# hercules_dcan_spec_1.4.1 register map
Vendor: Texas Instruments
Peripheral module from a debugger description file (folder hercules).
Registers are 32-bit, read-only, reset 0x0 unless marked. A register's access mark holds for its fields unless they carry their own. Offsets are as the file gives them; lines under a group give offsets from that group; [hi:lo] are bit positions; {n}, {i} and the like mark numbered series; 'fields as' and 'values as' point back to an identical list; <NAME> marks a mode.

## Dcan
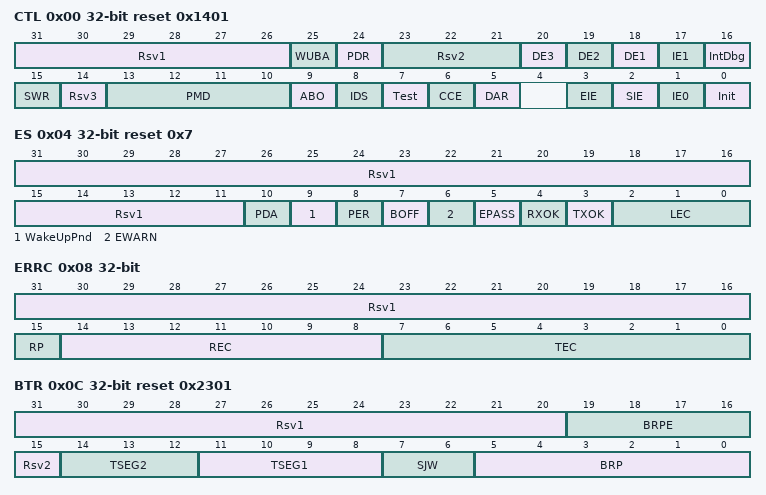
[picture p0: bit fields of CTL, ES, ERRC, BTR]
0x00 CTL access per field reset 0x1401 — CAN Control Register
  [31:26] Rsv1 ro — Reserved
  [25] WUBA rw — 1 = Enables Auto Wake Up on Bus Activity
  [24] PDR rw — 1 = Requests Local Low Power Down Mode
  [23:21] Rsv2 ro — Reserved
  [20] DE3 rw — 1 = Enable DMA Request for IF3
  [19] DE2 rw — 1 = Enable DMA Request for IF2
  [18] DE1 rw — 1 = Enable DMA Request for IF1
  [17] IE1 rw — 1 = Enables DCAN1INT
  [16] IntDbg ro — 1 = Debug Mode Requested and Entered
  [15] SWR rw — 1 = Software Reset Enable
  [14] Rsv3 ro — Reserved
  [13:10] PMD rw — 0xA=SECDED Disabled, Otherwise Enabled
  [9] ABO rw — 1 = Auto Bus On Enabled
  [8] IDS rw — 1 = Interrupt Transmission and Enter Debug Immediately
  [7] Test rw — 1 = Test Mode Enable
  [6] CCE rw — 1 = Configuration Change Enable (BTR Configuration)
  [5] DAR rw — 1 = Disable Automatic Retransmission
  [3] EIE rw — 1 = PER, BOFF, and EWARN Errors Enabled to generate DCAN0INT
  [2] SIE rw — 1 = WakeUpPnd, RxOk, and LEC Bits Generate DCAN0INT
  [1] IE0 rw — 1 = Interrupt Enable for DCAN0INT
  [0] Init rw — 1 = Initialization Mode Entered
0x04 ES access per field reset 0x7 — Error and Status register
  [31:11] Rsv1 ro — Reserved
  [10] PDA rw — 1 = DCAN Is Powered Down
  [9] WakeUpPnd rw — 1 = DCAN Initiated a WakeUp To System
  [8] PER rw — 1 = SECDED Detected Single/Double Bit Error
  [7] BOFF rw — 1 = BUS Off State
  [6] EWARN rw — 1 = Error Warning State, 1+ Error Counter >= 96
  [5] EPASS rw — 1 = Error Passive State
  [4] RXOK ro — 1 = Message Successfully Received
  [3] TXOK rw — 1 = Message Successfully Transmitted
  [2:0] LEC rw — 1 = Initialization Mode Entered
0x08 ERRC — Error Counter Register
  [31:16] Rsv1 — Reserved
  [15] RP — Receive Error Passive
  [14:8] REC — Receive Error Count
  [7:0] TEC — Transmit Error Count
0x0C BTR access per field reset 0x2301 — BIT Timing Register
  [31:20] Rsv1 ro — Reserved
  [19:16] BRPE rw — Baud Rate Prescaler Extension
  [15] Rsv2 ro — Reserved
  [14:12] TSEG2 rw — Time Segment After Sample Point
  [11:8] TSEG1 rw — Time Segment Before Sample Point
  [7:6] SJW rw — Sync Jump Width
  [5:0] BRP rw — Baud Rate Prescaler
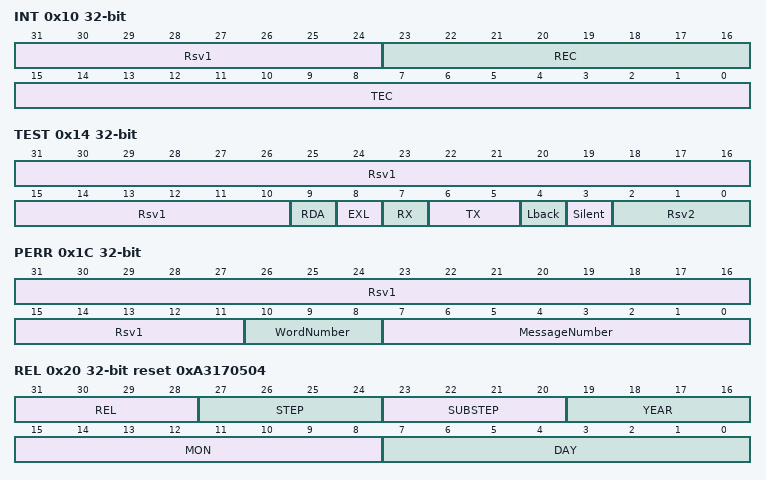
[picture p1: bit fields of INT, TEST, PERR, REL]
0x10 INT — Interrupt Register
  [31:24] Rsv1 — Reserved
  [23:16] REC — Int1ID 0x00 = No Int, 0x01-0x80 = Message Object #, Others Unused
  [15:0] TEC — Int0ID 0x00 = No Int, 0x01-0x80 = Message Object #, 0x8000 = Error Interrupt, Others Unused
0x14 TEST access per field
  [31:10] Rsv1 ro — Reserved
  [9] RDA rw — 1 = Enable Direct Access to RAM in Test Mode
  [8] EXL rw — 1 = Enable External Loopback
  [7] RX ro — 0 = CAN Bus is Dominant, 1=Recessive
  [6:5] TX rw — Control CANTX 0=Normal,1=Sample Pt. Monitor, 2= Drive Dom., 3=Drive Rec.
  [4] Lback rw — 1 = Enable Loopback
  [3] Silent rw — 1 = Silent Mode Enabled
  [2:0] Rsv2 ro — Reserved
0x1C PERR — Parity Error Code Register
  [31:11] Rsv1 — Reserved
  [10:8] WordNumber — Reserved - Always Reads 0
  [7:0] MessageNumber — 0x1-0x80 Message Number where Double Bit Error Detected
0x20 REL reset 0xA3170504 — Core Release Register
  [31:28] REL — Core Release
  [27:24] STEP — Step of Core Release
  [23:20] SUBSTEP — Substep of Core Release
  [19:16] YEAR
  [15:8] MON — Month
  [7:0] DAY
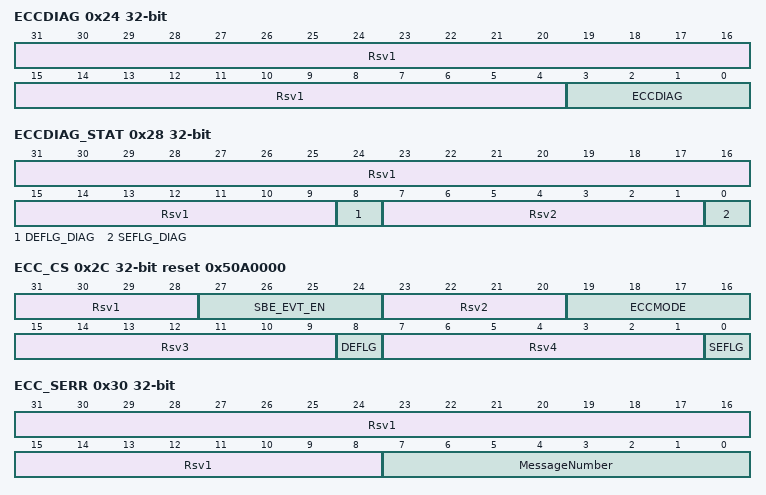
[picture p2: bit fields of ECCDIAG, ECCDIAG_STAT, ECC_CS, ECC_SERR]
0x24 ECCDIAG access per field — ECC Diagnostic Register
  [31:4] Rsv1 ro — Reserved
  [3:0] ECCDIAG rw — Diagnostic Mode 0x5=Enabled, 0xA=Disabled
0x28 ECCDIAG_STAT — ECC Diagnostic Status Register
  [31:9] Rsv1 — Reserved
  [8] DEFLG_DIAG — 1 = Double Bit Error Detected in Diagnostic Mode
  [7:1] Rsv2 — Reserved
  [0] SEFLG_DIAG — 1 = Single Bit Error Detected in Diagnostic Mode
0x2C ECC_CS access per field reset 0x50A0000 — ECC Control and Status Register
  [31:28] Rsv1 ro — Reserved
  [27:24] SBE_EVT_EN rw — 0x5 SECDED single bit error event disabled, Others Enabled
  [23:20] Rsv2 ro — Reserved
  [19:16] ECCMODE rw — 0x5 SECDED Disabled, Others SECDED Enabled
  [15:9] Rsv3 ro — Reserved
  [8] DEFLG rw — 1 = Double Bit Error Detected
  [7:1] Rsv4 ro — Reserved
  [0] SEFLG rw — 1 = Single Bit Error Detected
0x30 ECC_SERR — ECC Single Bit Error Code Register
  [31:8] Rsv1 — Reserved
  [7:0] MessageNumber — 0x1-0x80 Message Number where Double Bit Error Detected
0x80 ABOTR rw — Auto-Bus-On Time Register
  [31:0] ABO_TIME — Auto Bus On Time Counter
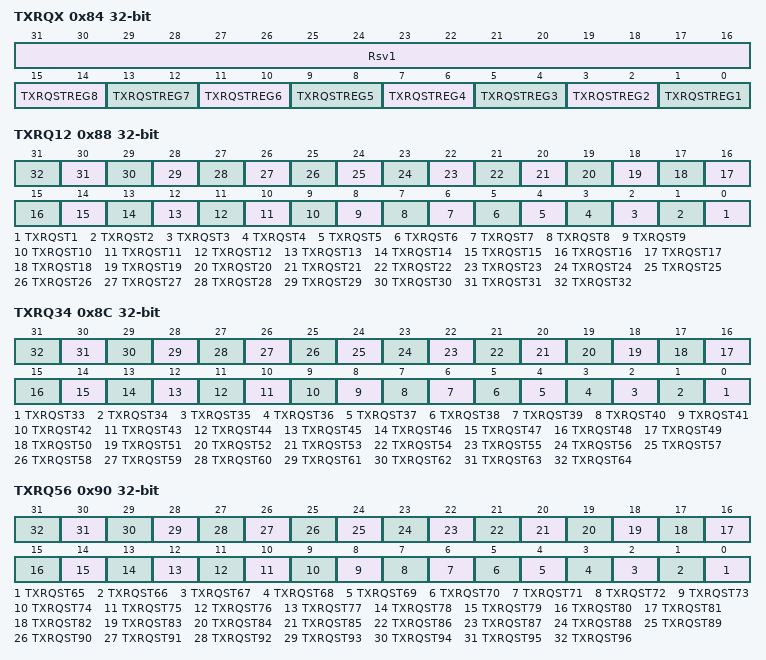
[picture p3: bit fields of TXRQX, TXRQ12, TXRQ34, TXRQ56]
0x84 TXRQX — Transmission Request X
  [31:16] Rsv1 — Reserved
  [2n-1:2n-2] TXRQSTREG{n} (n=1..8) — Not Zero = One or More Bits of TXRQ{n} are Set
0x88 TXRQ12 — Transmission Request 12 Register
  [n-1] TXRQST{n} (n=1..32) — 1 = Transmission of Message Object {n} Requested and not yet done
0x8C TXRQ34 — Transmission Request 34 Register
  [n-33] TXRQST{n} (n=33..64) — 1 = Transmission of Message Object {n} Requested and not yet done
0x90 TXRQ56 — Transmission Request 56 Register
  [n-65] TXRQST{n} (n=65..96) — 1 = Transmission of Message Object {n} Requested and not yet done
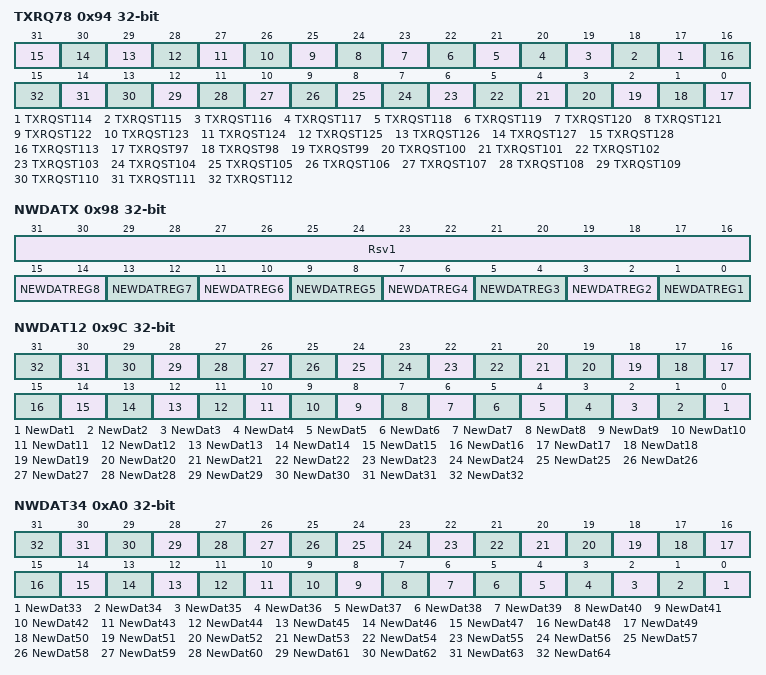
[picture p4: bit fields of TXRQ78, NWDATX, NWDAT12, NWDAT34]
0x94 TXRQ78 — Transmission Request 78 Register
  [n-97] TXRQST{n} (n=114..128) — 1 = Transmission of Message Object {n} Requested and not yet done
  [16] TXRQST113 — 1 = Transmission of Message Object 112 Requested and not yet done
  [n-97] TXRQST{n} (n=97..112) — 1 = Transmission of Message Object {n} Requested and not yet done
0x98 NWDATX — New Data X Register
  [31:16] Rsv1 — Reserved
  [2n-1:2n-2] NEWDATREG{n} (n=1..8) — Not Zero = One or More Bits of NWDAT{n} are Set
0x9C NWDAT12 — New Data 12 Register
  [n-1] NewDat{n} (n=1..32) — Message Handler or CPU has Written New Data To Message Object {n}
0xA0 NWDAT34 — New Data 34 Register
  [n-33] NewDat{n} (n=33..64) — Message Handler or CPU has Written New Data To Message Object {n}
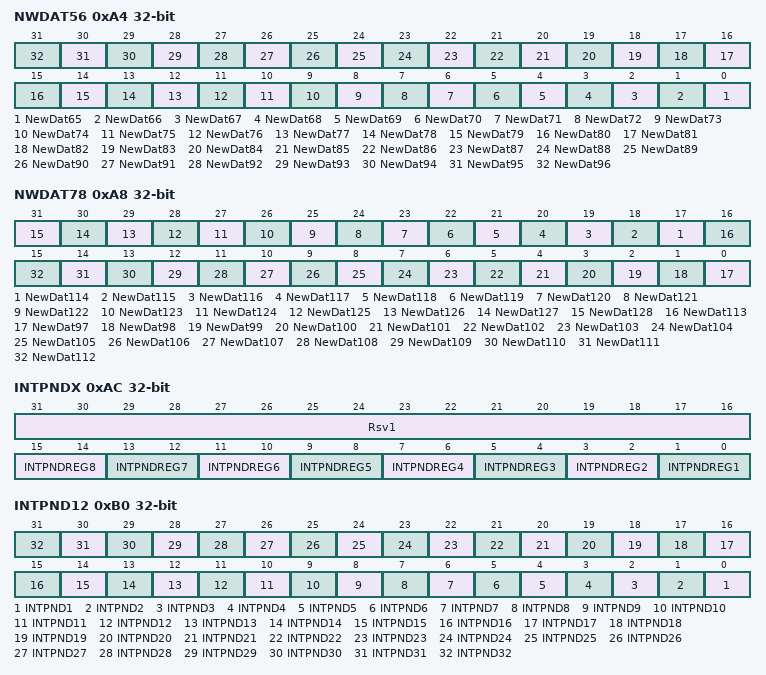
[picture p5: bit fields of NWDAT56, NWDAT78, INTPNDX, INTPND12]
0xA4 NWDAT56 — New Data 56 Register
  [n-65] NewDat{n} (n=65..96) — Message Handler or CPU has Written New Data To Message Object {n}
0xA8 NWDAT78 — New Data 78 Register
  [n-97] NewDat{n} (n=114..128) — Message Handler or CPU has Written New Data To Message Object {n}
  [16] NewDat113 — Message Handler or CPU has Written New Data To Message Object 112
  [n-97] NewDat{n} (n=97..112) — Message Handler or CPU has Written New Data To Message Object {n}
0xAC INTPNDX — Interrupt Pending X Register
  [31:16] Rsv1 — Reserved
  [2n-1:2n-2] INTPNDREG{n} (n=1..8) — Not Zero = One or More Bits of INTPND{n} are Set
0xB0 INTPND12 — Interrupt Pending 12 Register
  [n-1] INTPND{n} (n=1..32) — Message Object {n} Interrupt Pending
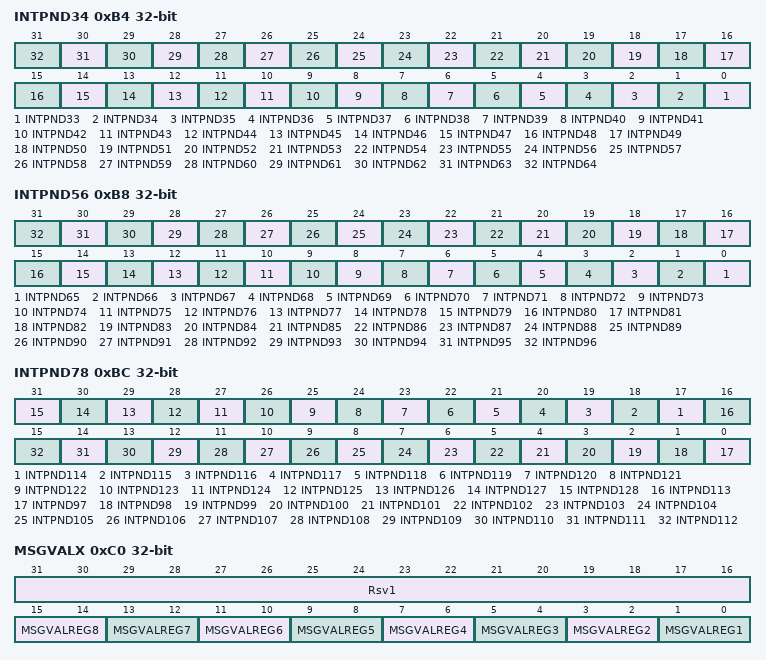
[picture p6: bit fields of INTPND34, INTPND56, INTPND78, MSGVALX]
0xB4 INTPND34 — Interrupt Pending 34 Register
  [n-33] INTPND{n} (n=33..64) — Message Object {n} Interrupt Pending
0xB8 INTPND56 — Interrupt Pending 56 Register
  [n-65] INTPND{n} (n=65..96) — Message Object {n} Interrupt Pending
0xBC INTPND78 — Interrupt Pending 78 Register
  [n-97] INTPND{n} (n=114..128) — Message Object {n} Interrupt Pending
  [16] INTPND113 — Message Object 112 Interrupt Pending
  [n-97] INTPND{n} (n=97..112) — Message Object {n} Interrupt Pending
0xC0 MSGVALX — Message Valid X Register
  [31:16] Rsv1 — Reserved
  [2n-1:2n-2] MSGVALREG{n} (n=1..8) — Not Zero = One or More Bits of MSGVAL{n} are Set
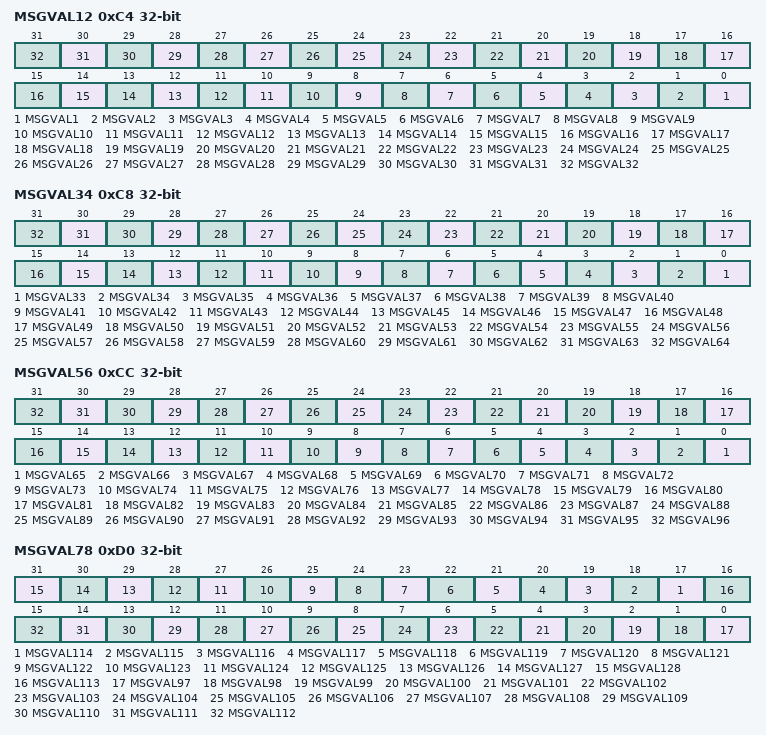
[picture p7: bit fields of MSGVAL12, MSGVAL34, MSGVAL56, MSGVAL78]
0xC4 MSGVAL12 — Message Valid 12 Register
  [n-1] MSGVAL{n} (n=1..32) — 1 = Message Object {n} Is Configured and Will Be Considered by The Message Handler
0xC8 MSGVAL34 — Message Valid 34 Register
  [n-33] MSGVAL{n} (n=33..64) — 1 = Message Object {n} Is Configured and Will Be Considered by The Message Handler
0xCC MSGVAL56 — Message Valid 56 Register
  [n-65] MSGVAL{n} (n=65..96) — 1 = Message Object {n} Is Configured and Will Be Considered by The Message Handler
0xD0 MSGVAL78 — Message Valid 78 Register
  [n-97] MSGVAL{n} (n=114..128) — 1 = Message Object {n} Is Configured and Will Be Considered by The Message Handler
  [16] MSGVAL113 — 1 = Message Object 112 Is Configured and Will Be Considered by The Message Handler
  [n-97] MSGVAL{n} (n=97..112) — 1 = Message Object {n} Is Configured and Will Be Considered by The Message Handler
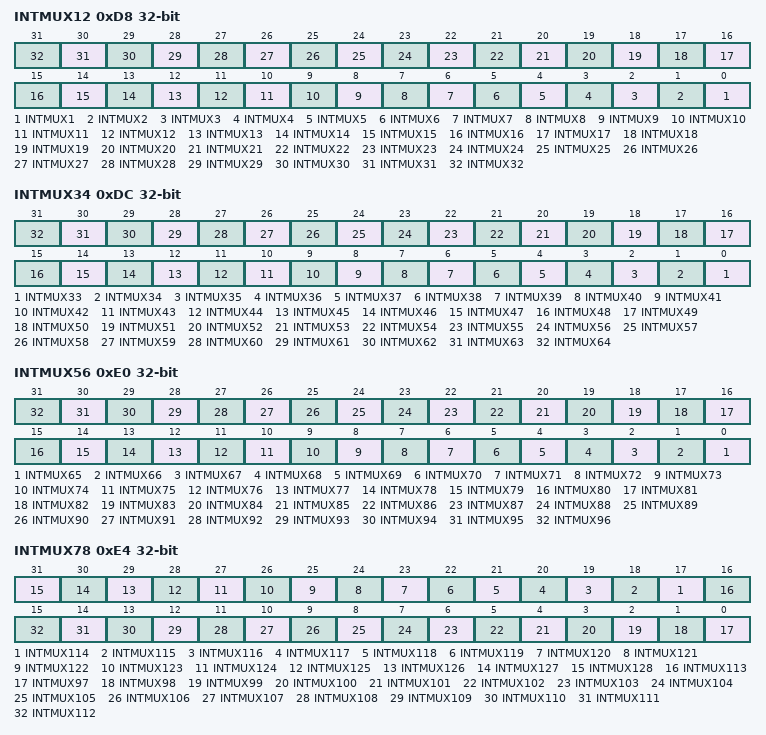
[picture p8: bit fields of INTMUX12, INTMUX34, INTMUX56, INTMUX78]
0xD8 INTMUX12 rw — Interrupt Multiplexer 12 Register
  [n-1] INTMUX{n} (n=1..32) — Message Object {n} Interrupt Mux: 1=DCAN1INT, 0=DCAN0INT
0xDC INTMUX34 rw — Interrupt Multiplexer 34 Register
  [n-33] INTMUX{n} (n=33..64) — Message Object {n} Interrupt Mux: 1=DCAN1INT, 0=DCAN0INT
0xE0 INTMUX56 rw — Interrupt Multiplexer 56 Register
  [n-65] INTMUX{n} (n=65..96) — Message Object {n} Interrupt Mux: 1=DCAN1INT, 0=DCAN0INT
0xE4 INTMUX78 rw — Interrupt Multiplexer 78 Register
  [n-97] INTMUX{n} (n=114..128) — Message Object {n} Interrupt Mux: 1=DCAN1INT, 0=DCAN0INT
  [16] INTMUX113 — Message Object 112 Interrupt Mux: 1=DCAN1INT, 0=DCAN0INT
  [n-97] INTMUX{n} (n=97..112) — Message Object {n} Interrupt Mux: 1=DCAN1INT, 0=DCAN0INT
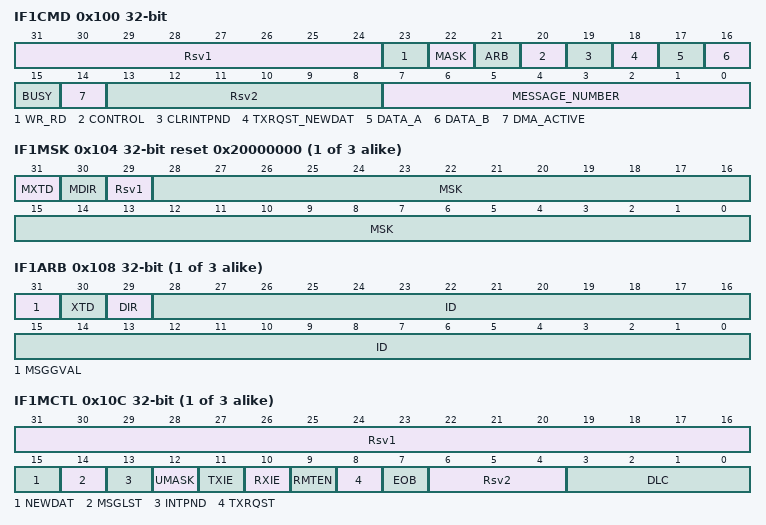
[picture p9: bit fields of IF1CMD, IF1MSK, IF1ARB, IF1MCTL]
0x100 IF1CMD access per field — IF1 Command Register
  [31:24] Rsv1 ro — Reserved
  [23] WR_RD rw — 0=Read: Message Object->IF, 1=Write: IF->Message Object
  [22] MASK rw — 0=Mask Bits Unchanged, 1=Mask Bits Transferred
  [21] ARB rw — 0=Arb Bits Unchanged, 1=Arb Bits Transferred
  [20] CONTROL rw — 0=Control Bits Unchanged, 1=Control Bits Transferred
  [19] CLRINTPND rw — 0=Interrupt Pending Unchanged, 1= Clear on Reads
  [18] TXRQST_NEWDAT rw — Reads: Newdat Unchanged on 0, Clear on 1. Writes: TxRqst/NewDat: 0=Control Determines Set, 1=Set
  [17] DATA_A rw — Data Bytes 0-3: 0=Unchanged, 1=Transferred
  [16] DATA_B rw — Data Bytes 4-7: 0=Unchanged, 1=Transferred
  [15] BUSY ro — 1 = Transfer In Progress
  [14] DMA_ACTIVE rw — 1 = DMA Request after Transfer
  [13:8] Rsv2 ro — Reserved
  [7:0] MESSAGE_NUMBER rw — Message Object Number for Transfer 0x1-0x80 Valid
{0xE4+0x20*i} IF{i}MSK access per field reset 0x20000000 (i=1..3) — IF{i} Mask Register
  [31] MXTD rw — Extended Identifer (IDE) Used For Filtering 0=No, 1=Yes
  [30] MDIR rw — Message Direction Bit (DIR) Used For Filtering 0=No, 1=Yes
  [29] Rsv1 ro — Reserved
  [28:0] MSK rw — Identifier Mask 0=Not Used, 1=Used for Acceptance Filtering
{0xE8+0x20*i} IF{i}ARB rw (i=1..3) — IF{i} Arbitation Register
  [31] MSGGVAL — Message Valid 0=No, 1=Yes
  [30] XTD — Extended Identifier 0=11 bit, 1=29 Bit
  [29] DIR — Message Direction 0=Receive, 1=Transmit
  [28:0] ID — Message Identifier
{0xEC+0x20*i} IF{i}MCTL access per field (i=1..3) — IF{i} Message Control Register
  [31:16] Rsv1 ro — Reserved
  [15] NEWDAT rw — 1 = New Data Written to Data Portion of Message
  [14] MSGLST rw — 1 = Previous Message Overwritten
  [13] INTPND rw — 1 = Interrupt Pending
  [12] UMASK rw — 1 = Use Mask MSK[28:0],MXTD,MDIR for Filtering, 0=Mask Ignored
  [11] TXIE rw — 1 = IntPnd will be triggered after successful transmission of frame
  [10] RXIE rw — 1 = IntPnd will be triggered after successful reception of frame
  [9] RMTEN rw — 1 = At the reception of a remote frame TXRQST is set
  [8] TXRQST rw — 1 = Tranmission of Message Object Requested And Not Yet Done
  [7] EOB rw — 1 = Concatenates multiple messages to build a FIFO buffer
  [6:4] Rsv2 ro — Reserved
  [3:0] DLC rw — Data Length Code 0-8 Data Frame has 0-8 bits, 9-F Data Frame has 8 Bytes
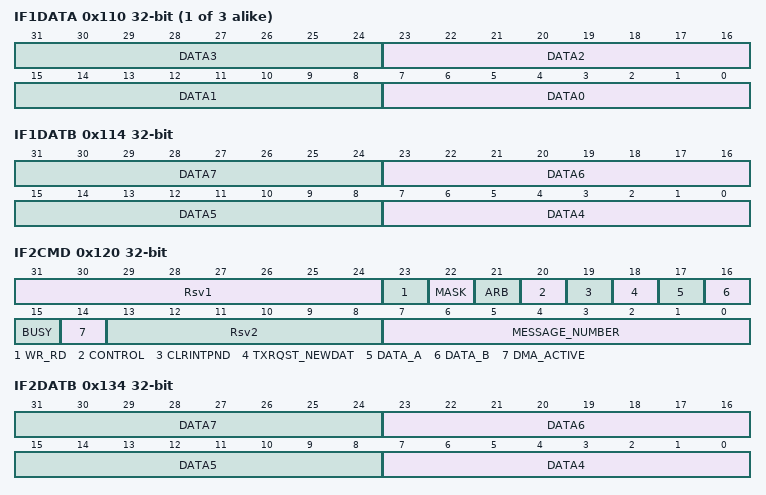
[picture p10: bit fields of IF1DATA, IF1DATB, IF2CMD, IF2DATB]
{0xF0+0x20*i} IF{i}DATA rw (i=1..3) — IF{i} Data A Register
  [8n+7:8n] DATA{n} (n=0..3) — Message Data Byte {n}
0x114 IF1DATB rw — IF1 Data B Register
  [8n-25:8n-32] DATA{n} (n=4..7) — Message Data Byte {n-4}
0x120 IF2CMD access per field — IF2 Command Register
  fields as IF1CMD
0x134 IF2DATB rw — IF2 Data B Register
  [8n-25:8n-32] DATA{n} (n=4..7) — Message Data Byte {n}
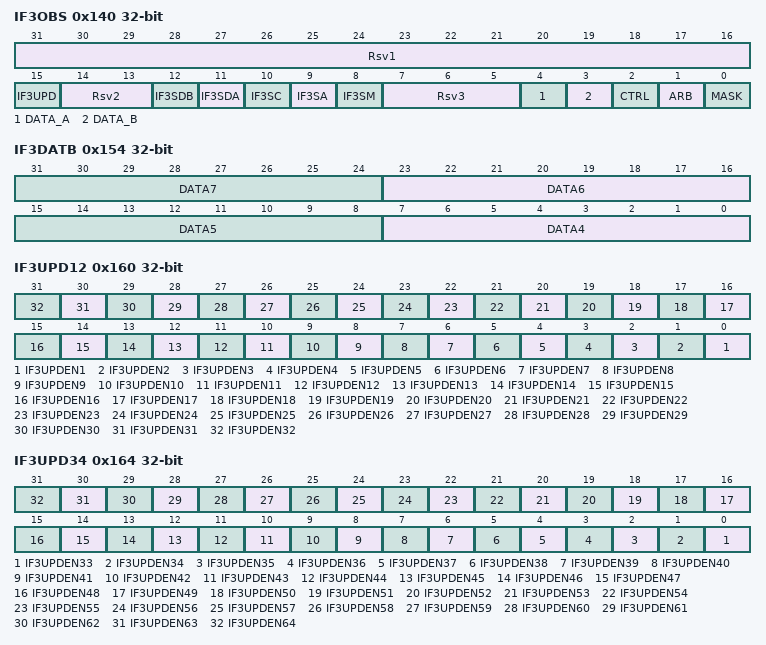
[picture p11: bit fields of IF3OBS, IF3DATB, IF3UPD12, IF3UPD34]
0x140 IF3OBS access per field — IF3 Observation Register
  [31:16] Rsv1 ro — Reserved
  [15] IF3UPD ro — 1 = New Data Loaded Since IF3 Last Read
  [14:13] Rsv2 ro — Reserved
  [12] IF3SDB ro — 1 = Data B Still has Data to Read
  [11] IF3SDA ro — 1 = Data A Still has Data to Read
  [10] IF3SC ro — 1 = Control Still Has Data To Read
  [9] IF3SA ro — 1 = Arb Still Has Data To Read
  [8] IF3SM ro — 1 = Mask Section Still Has Data To Read
  [7:5] Rsv3 rw — Reserved
  [4] DATA_A rw — 1 = Data A Must Be Read to Enable Next IF3 Update
  [3] DATA_B rw — 1 = Data B Must Be Read to Enable Next IF3 Update
  [2] CTRL rw — 1 = Control Must Be Read to Enable Next IF3 Update
  [1] ARB rw — 1 = Arb Must Be Read to Enable Next IF3 Update
  [0] MASK rw — 1 = Mask Must Be Read to Enable Next IF3 Update
0x154 IF3DATB rw — IF3 Data B Register
  [8n-25:8n-32] DATA{n} (n=4..7) — Message Data Byte {n}
0x160 IF3UPD12 rw — IF3 Update Enable 12 Register
  [n-1] IF3UPDEN{n} (n=1..32) — Automatic IF3 Update Enabled for Message Object {n}
0x164 IF3UPD34 rw — IF3 Update Enable 34 Register
  [n-33] IF3UPDEN{n} (n=33..64) — Automatic IF3 Update Enabled for Message Object {n}
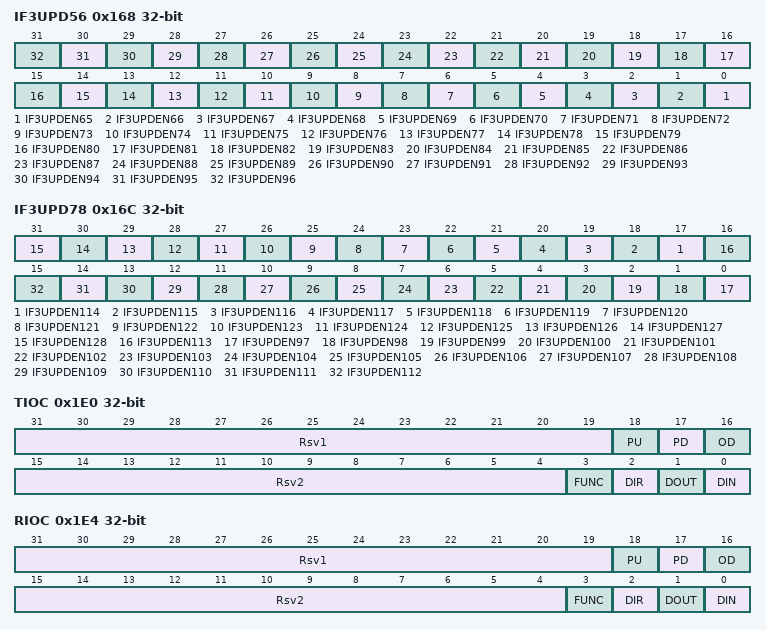
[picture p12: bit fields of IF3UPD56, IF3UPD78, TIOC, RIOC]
0x168 IF3UPD56 rw — IF3 Update Enable 56 Register
  [n-65] IF3UPDEN{n} (n=65..96) — Automatic IF3 Update Enabled for Message Object {n}
0x16C IF3UPD78 rw — IF3 Update Enable 78 Register
  [n-97] IF3UPDEN{n} (n=114..128) — Automatic IF3 Update Enabled for Message Object {n}
  [16] IF3UPDEN113 — Automatic IF3 Update Enabled for Message Object 112
  [n-97] IF3UPDEN{n} (n=97..112) — Automatic IF3 Update Enabled for Message Object {n}
0x1E0 TIOC access per field — TX IO Control Register
  [31:19] Rsv1 ro — Reserved
  [18] PU rw — CANTX Pullup/Down Select 0=PullDown, 1=PullUp
  [17] PD rw — CANTX Pull Enable 0 = Pull Up/Down Active, 1 = Pull Up/Down Disabled
  [16] OD rw — CANTX Open-Drain Enable 0 = Push/Pull, 1 = Open-Drain
  [15:4] Rsv2 ro — Reserved
  [3] FUNC rw — CANTX Pin Function 0=GIO, 1=CAN
  [2] DIR rw — CANTX GIO Direction 0=Input, 1=Output
  [1] DOUT rw — CANTX GIO Data Out
  [0] DIN rw — CANTX GIO Data In
0x1E4 RIOC access per field — RX IO Control Register
  [31:19] Rsv1 ro — Reserved
  [18] PU rw — CANRX Pullup/Down Select 0=PullDown, 1=PullUp
  [17] PD rw — CANRX Pull Enable 0 = Pull Up/Down Active, 1 = Pull Up/Down Disabled
  [16] OD rw — CANRX Open-Drain Enable 0 = Push/Pull, 1 = Open-Drain
  [15:4] Rsv2 ro — Reserved
  [3] FUNC rw — CANRX Pin Function 0=GIO, 1=CAN
  [2] DIR rw — CANRX GIO Direction 0=Input, 1=Output
  [1] DOUT rw — CANRX GIO Data Out
  [0] DIN rw — CANRX GIO Data In

## Notices in the file
(c) Texas Instruments 2003-2014, All rights reserved.
